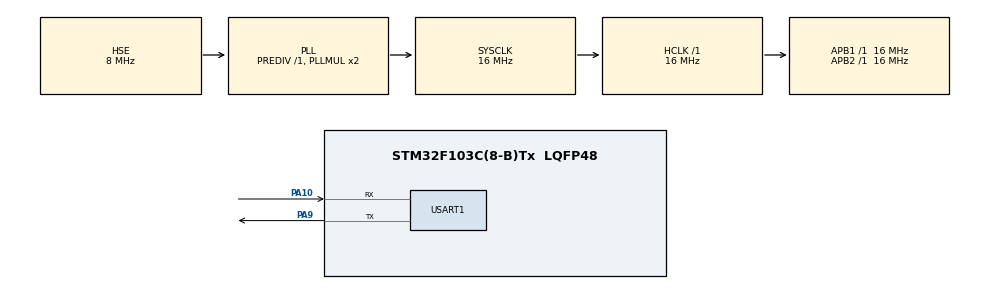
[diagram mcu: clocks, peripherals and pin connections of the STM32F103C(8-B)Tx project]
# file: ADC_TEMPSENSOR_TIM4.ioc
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ADC1.Channel-4\#ChannelRegularConversion=ADC_CHANNEL_TEMPSENSOR
ADC1.ExternalTrigConv=ADC_EXTERNALTRIGCONV_T4_CC4
ADC1.InjNumberOfConversion=0
ADC1.NbrOfConversion=1
ADC1.NbrOfConversionFlag=1
ADC1.Rank-4\#ChannelRegularConversion=1
ADC1.SamplingTime-4\#ChannelRegularConversion=ADC_SAMPLETIME_28CYCLES_5
ADC1.master=1
Dma.ADC1.0.Direction=DMA_PERIPH_TO_MEMORY
Dma.ADC1.0.Instance=DMA1_Channel1
Dma.ADC1.0.MemDataAlignment=DMA_MDATAALIGN_HALFWORD
Dma.ADC1.0.MemInc=DMA_MINC_ENABLE
Dma.ADC1.0.Mode=DMA_CIRCULAR
Dma.ADC1.0.PeriphDataAlignment=DMA_PDATAALIGN_HALFWORD
Dma.ADC1.0.PeriphInc=DMA_PINC_DISABLE
Dma.ADC1.0.Priority=DMA_PRIORITY_LOW
Dma.Request0=ADC1
Mcu.Family=STM32F1
Mcu.Name=STM32F103C(8-B)Tx
Mcu.Package=LQFP48
NVIC.DMA1_Channel1_IRQn=true\:0\:0\:false\:false\:true\:false\:true
NVIC.PriorityGroup=NVIC_PRIORITYGROUP_4
NVIC.TIM1_UP_IRQn=true\:0\:0\:false\:false\:true\:true\:true
NVIC.USART1_IRQn=true\:0\:0\:false\:false\:true\:true\:true
PA10.Mode=Asynchronous
PA10.Signal=USART1_RX
PA13.Mode=Serial_Wire
PA13.Signal=SYS_JTMS-SWDIO
PA14.Mode=Serial_Wire
PA14.Signal=SYS_JTCK-SWCLK
PA9.Mode=Asynchronous
PA9.Signal=USART1_TX
PD0-OSC_IN.Mode=HSE-External-Oscillator
PD0-OSC_IN.Signal=RCC_OSC_IN
PD1-OSC_OUT.Mode=HSE-External-Oscillator
PD1-OSC_OUT.Signal=RCC_OSC_OUT
ProjectManager.HeapSize=0x200
ProjectManager.StackSize=0x400
ProjectManager.TargetToolchain=TrueSTUDIO
RCC.AHBFreq_Value=16000000
RCC.APB1Freq_Value=16000000
RCC.APB1TimFreq_Value=16000000
RCC.APB2Freq_Value=16000000
RCC.APB2TimFreq_Value=16000000
RCC.HCLKFreq_Value=16000000
RCC.PLLSourceVirtual=RCC_PLLSOURCE_HSE
RCC.SYSCLKFreq_VALUE=16000000
RCC.SYSCLKSource=RCC_SYSCLKSOURCE_PLLCLK
RCC.USBFreq_Value=16000000
TIM1.Period=1000-1
TIM1.Prescaler=16000-1
TIM4.Channel-Output\ Compare4\ No\ Output=TIM_CHANNEL_4
TIM4.OCMode_4=TIM_OCMODE_TOGGLE
TIM4.Period=10-1
TIM4.Prescaler=16000-1
USART1.VirtualMode=VM_ASYNC
VP_ADC1_TempSens_Input.Mode=IN-TempSens
VP_TIM1_VS_ClockSourceINT.Mode=Internal
VP_TIM4_VS_no_output4.Mode=Output Compare4 No Output
board=custom

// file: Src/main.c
/* USER CODE BEGIN Header */
/**
  ******************************************************************************
  * @file           : main.c
  * @brief          : Main program body
  ******************************************************************************
  * @attention
  *
  * <h2><center>&copy; Copyright (c) 2019 STMicroelectronics.
  * All rights reserved.</center></h2>
  *
  * This software component is licensed by ST under BSD 3-Clause license,
  * the "License"; You may not use this file except in compliance with the
  * License. You may obtain a copy of the License at:
  *                        opensource.org/licenses/BSD-3-Clause
  *
  ******************************************************************************
  */
/* USER CODE END Header */

#include "main.h"

/* USER CODE BEGIN Includes */
#include <stdio.h> // for sprinf
#include <string.h> // for strlen
/* USER CODE END Includes */

ADC_HandleTypeDef hadc1;
DMA_HandleTypeDef hdma_adc1;

TIM_HandleTypeDef htim1;
TIM_HandleTypeDef htim4;

UART_HandleTypeDef huart1;

void SystemClock_Config(void);
static void MX_GPIO_Init(void);
static void MX_DMA_Init(void);
static void MX_ADC1_Init(void);
static void MX_TIM1_Init(void);
static void MX_TIM4_Init(void);
static void MX_USART1_UART_Init(void);

/* USER CODE BEGIN 0 */
volatile uint16_t adc_value;// АЦП результат полученный из DMA
volatile uint32_t adc_avg_value;// среднее значение АЦП
volatile uint16_t counter;// счётчик хранит сколько раз опрашивался АЦП
void HAL_ADC_ConvCpltCallback(ADC_HandleTypeDef* hadc)
{
	if(hadc->Instance == ADC1) //check if the interrupt comes from ACD1
    {
    	adc_avg_value += adc_value;
    	counter++;
    }
}
char str[20];
#define AVGSLOPE 4.3 // милли вольт  при изменении температуры на градус
//average slope of T-V chart according to datasheet pg 79
//(min is 4 mV/C, max 4.6, default (4.3): typical)
#define V25 1.43 // вольт на температурном датчике при температуре 25 °C
//voltage of temperature sensor at 25C according to datasheet pg 79 (in V)
//(min is 1.34, max is 1.52, default(1.43): typical)
uint16_t temperature;
void HAL_TIM_PeriodElapsedCallback(TIM_HandleTypeDef *htim)
{
	if(htim->Instance == TIM1) //check if the interrupt comes from TIM1
	{
		adc_avg_value /= counter;// получаем среднее значение ацп
		temperature = (uint16_t)(((V25 * 1000.0 - (float)adc_avg_value * 0.8) / AVGSLOPE) + 25.0);// расчёт температуры
		sprintf(str, "T=%d C, ADC=%lu, counter=%d \r\n", temperature, adc_avg_value,counter);
		HAL_UART_Transmit_IT(&huart1,(uint8_t*) str, strlen(str));
		adc_avg_value = counter = 0;// обязательный сброс
	}
}
/* USER CODE END 0 */

int main(void)
{

  /* MCU Configuration--------------------------------------------------------*/

  /* Reset of all peripherals, Initializes the Flash interface and the Systick. */
  HAL_Init();

  /* Configure the system clock */
  SystemClock_Config();

  /* Initialize all configured peripherals */
  MX_GPIO_Init();
  MX_DMA_Init();
  MX_ADC1_Init();
  MX_TIM1_Init();
  MX_TIM4_Init();
  MX_USART1_UART_Init();
  /* USER CODE BEGIN 2 */
  HAL_ADCEx_Calibration_Start(&hadc1);// калибровка АЦП
  HAL_ADC_Start_DMA(&hadc1, (uint32_t*)&adc_value, 1); // стартуем АЦП DMA
  HAL_TIM_OC_Start(&htim4, TIM_CHANNEL_4); // старт таймера TIM4 который запускает АЦП 50 раз в секунду
  HAL_TIM_Base_Start_IT(&htim1); // старт таймера  TIM1 который один раз в секунду запускает расчёт температуры и выводит результат в UART
  HAL_UART_Transmit_IT(&huart1,(uint8_t*) "start\n", 6);
  /* USER CODE END 2 */

  /* Infinite loop */
  while (1)
  {

  }
}

void SystemClock_Config(void)
{
  RCC_OscInitTypeDef RCC_OscInitStruct = {0};
  RCC_ClkInitTypeDef RCC_ClkInitStruct = {0};
  RCC_PeriphCLKInitTypeDef PeriphClkInit = {0};

  /** Initializes the CPU, AHB and APB busses clocks
  */
  RCC_OscInitStruct.OscillatorType = RCC_OSCILLATORTYPE_HSE;
  RCC_OscInitStruct.HSEState = RCC_HSE_ON;
  RCC_OscInitStruct.HSEPredivValue = RCC_HSE_PREDIV_DIV1;
  RCC_OscInitStruct.HSIState = RCC_HSI_ON;
  RCC_OscInitStruct.PLL.PLLState = RCC_PLL_ON;
  RCC_OscInitStruct.PLL.PLLSource = RCC_PLLSOURCE_HSE;
  RCC_OscInitStruct.PLL.PLLMUL = RCC_PLL_MUL2;
  if (HAL_RCC_OscConfig(&RCC_OscInitStruct) != HAL_OK)
  {
    Error_Handler();
  }
  /** Initializes the CPU, AHB and APB busses clocks
  */
  RCC_ClkInitStruct.ClockType = RCC_CLOCKTYPE_HCLK|RCC_CLOCKTYPE_SYSCLK
                              |RCC_CLOCKTYPE_PCLK1|RCC_CLOCKTYPE_PCLK2;
  RCC_ClkInitStruct.SYSCLKSource = RCC_SYSCLKSOURCE_PLLCLK;
  RCC_ClkInitStruct.AHBCLKDivider = RCC_SYSCLK_DIV1;
  RCC_ClkInitStruct.APB1CLKDivider = RCC_HCLK_DIV1;
  RCC_ClkInitStruct.APB2CLKDivider = RCC_HCLK_DIV1;

  if (HAL_RCC_ClockConfig(&RCC_ClkInitStruct, FLASH_LATENCY_0) != HAL_OK)
  {
    Error_Handler();
  }
  PeriphClkInit.PeriphClockSelection = RCC_PERIPHCLK_ADC;
  PeriphClkInit.AdcClockSelection = RCC_ADCPCLK2_DIV2;
  if (HAL_RCCEx_PeriphCLKConfig(&PeriphClkInit) != HAL_OK)
  {
    Error_Handler();
  }
}

static void MX_ADC1_Init(void)
{

  ADC_ChannelConfTypeDef sConfig = {0};

  /** Common config
  */
  hadc1.Instance = ADC1;
  hadc1.Init.ScanConvMode = ADC_SCAN_DISABLE;
  hadc1.Init.ContinuousConvMode = DISABLE;
  hadc1.Init.DiscontinuousConvMode = DISABLE;
  hadc1.Init.ExternalTrigConv = ADC_EXTERNALTRIGCONV_T4_CC4;
  hadc1.Init.DataAlign = ADC_DATAALIGN_RIGHT;
  hadc1.Init.NbrOfConversion = 1;
  if (HAL_ADC_Init(&hadc1) != HAL_OK)
  {
    Error_Handler();
  }
  /** Configure Regular Channel
  */
  sConfig.Channel = ADC_CHANNEL_TEMPSENSOR;
  sConfig.Rank = ADC_REGULAR_RANK_1;
  sConfig.SamplingTime = ADC_SAMPLETIME_28CYCLES_5;
  if (HAL_ADC_ConfigChannel(&hadc1, &sConfig) != HAL_OK)
  {
    Error_Handler();
  }

}

static void MX_TIM1_Init(void)
{

  TIM_ClockConfigTypeDef sClockSourceConfig = {0};
  TIM_MasterConfigTypeDef sMasterConfig = {0};

  htim1.Instance = TIM1;
  htim1.Init.Prescaler = 16000-1;
  htim1.Init.CounterMode = TIM_COUNTERMODE_UP;
  htim1.Init.Period = 1000-1;
  htim1.Init.ClockDivision = TIM_CLOCKDIVISION_DIV1;
  htim1.Init.RepetitionCounter = 0;
  htim1.Init.AutoReloadPreload = TIM_AUTORELOAD_PRELOAD_DISABLE;
  if (HAL_TIM_Base_Init(&htim1) != HAL_OK)
  {
    Error_Handler();
  }
  sClockSourceConfig.ClockSource = TIM_CLOCKSOURCE_INTERNAL;
  if (HAL_TIM_ConfigClockSource(&htim1, &sClockSourceConfig) != HAL_OK)
  {
    Error_Handler();
  }
  sMasterConfig.MasterOutputTrigger = TIM_TRGO_RESET;
  sMasterConfig.MasterSlaveMode = TIM_MASTERSLAVEMODE_DISABLE;
  if (HAL_TIMEx_MasterConfigSynchronization(&htim1, &sMasterConfig) != HAL_OK)
  {
    Error_Handler();
  }

}

static void MX_TIM4_Init(void)
{

  TIM_MasterConfigTypeDef sMasterConfig = {0};
  TIM_OC_InitTypeDef sConfigOC = {0};

  htim4.Instance = TIM4;
  htim4.Init.Prescaler = 16000-1;
  htim4.Init.CounterMode = TIM_COUNTERMODE_UP;
  htim4.Init.Period = 10-1;
  htim4.Init.ClockDivision = TIM_CLOCKDIVISION_DIV1;
  htim4.Init.AutoReloadPreload = TIM_AUTORELOAD_PRELOAD_DISABLE;
  if (HAL_TIM_OC_Init(&htim4) != HAL_OK)
  {
    Error_Handler();
  }
  sMasterConfig.MasterOutputTrigger = TIM_TRGO_RESET;
  sMasterConfig.MasterSlaveMode = TIM_MASTERSLAVEMODE_DISABLE;
  if (HAL_TIMEx_MasterConfigSynchronization(&htim4, &sMasterConfig) != HAL_OK)
  {
    Error_Handler();
  }
  sConfigOC.OCMode = TIM_OCMODE_TOGGLE;
  sConfigOC.Pulse = 0;
  sConfigOC.OCPolarity = TIM_OCPOLARITY_HIGH;
  sConfigOC.OCFastMode = TIM_OCFAST_DISABLE;
  if (HAL_TIM_OC_ConfigChannel(&htim4, &sConfigOC, TIM_CHANNEL_4) != HAL_OK)
  {
    Error_Handler();
  }

}

static void MX_USART1_UART_Init(void)
{

  huart1.Instance = USART1;
  huart1.Init.BaudRate = 115200;
  huart1.Init.WordLength = UART_WORDLENGTH_8B;
  huart1.Init.StopBits = UART_STOPBITS_1;
  huart1.Init.Parity = UART_PARITY_NONE;
  huart1.Init.Mode = UART_MODE_TX_RX;
  huart1.Init.HwFlowCtl = UART_HWCONTROL_NONE;
  huart1.Init.OverSampling = UART_OVERSAMPLING_16;
  if (HAL_UART_Init(&huart1) != HAL_OK)
  {
    Error_Handler();
  }

}

static void MX_DMA_Init(void)
{

  /* DMA controller clock enable */
  __HAL_RCC_DMA1_CLK_ENABLE();

  /* DMA interrupt init */
  /* DMA1_Channel1_IRQn interrupt configuration */
  HAL_NVIC_SetPriority(DMA1_Channel1_IRQn, 0, 0);
  HAL_NVIC_EnableIRQ(DMA1_Channel1_IRQn);

}

static void MX_GPIO_Init(void)
{

  /* GPIO Ports Clock Enable */
  __HAL_RCC_GPIOD_CLK_ENABLE();
  __HAL_RCC_GPIOA_CLK_ENABLE();

}

void Error_Handler(void)
{
}

/************************ (C) COPYRIGHT STMicroelectronics *****END OF FILE****/
